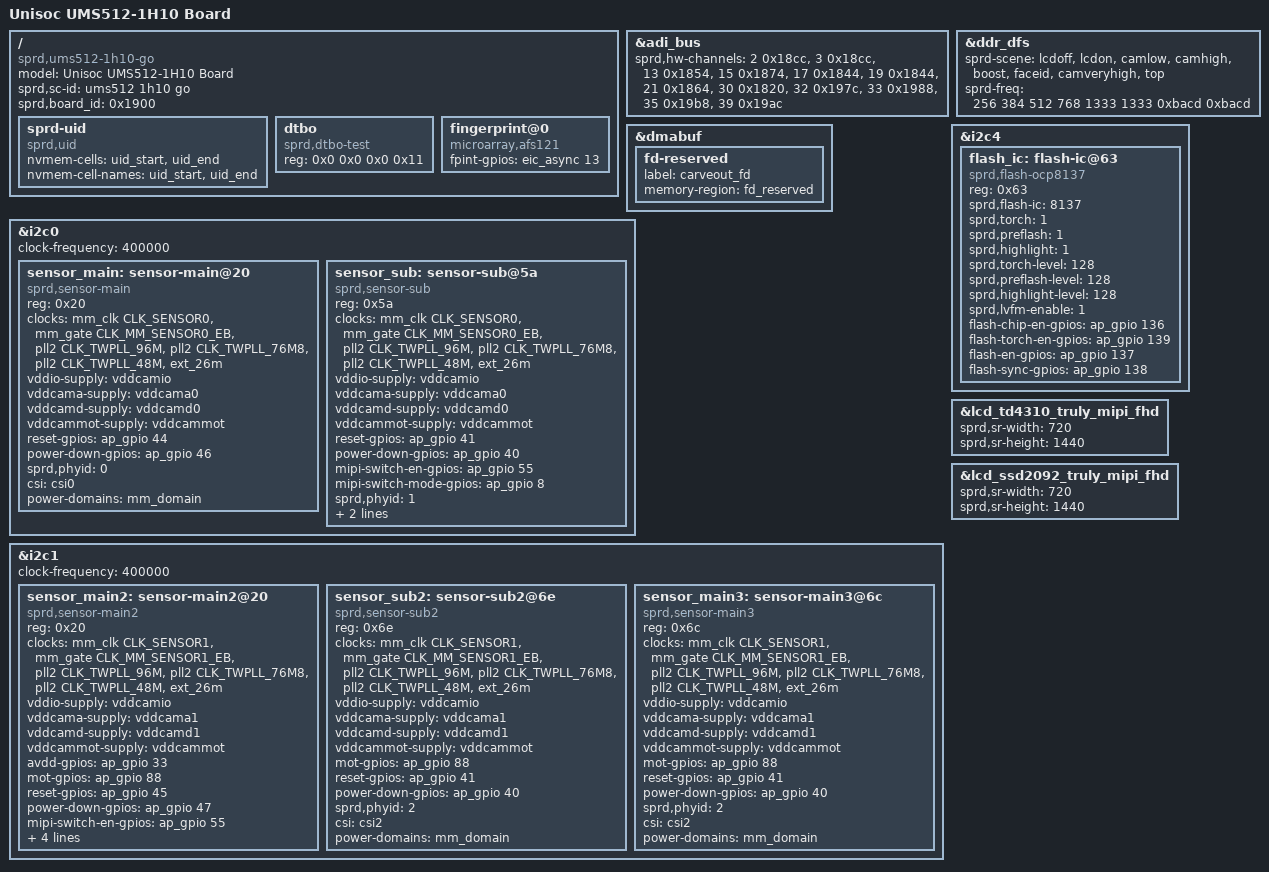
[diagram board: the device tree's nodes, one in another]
/dts-v1/;
/plugin/;

#include <dt-bindings/clock/sprd,ums512-clk.h>
#include <dt-bindings/gpio/gpio.h>
#include <dt-bindings/interrupt-controller/arm-gic.h>
#include "lcd/lcd_td4310_truly_mipi_fhd.dtsi"
#include "lcd/lcd_ssd2092_truly_mipi_fhd.dtsi"
#include "lcd/lcd_dummy_mipi.dtsi"
#include "reserved-memory/ums512-1h10-go-overlay.dtsi"
#include "battery/ums512-1h10-go-overlay.dtsi"
#include "touchscreen/ums512-i2c3-gpio144-145-tp.dtsi"

/ {
	model = "Unisoc UMS512-1H10 Board";
	compatible = "sprd,ums512-1h10-go", "sprd,ums512";
	sprd,sc-id = "ums512 1h10 go";
	sprd,board_id = <0x1900>; //XX00:base board,XX00~XXFF:customize board

	fragment {
		target-path = "/";
		__overlay__ {
			#address-cells = <2>;
			#size-cells = <2>;

			dtbo: dtbo {
				compatible = "sprd,dtbo-test";
				reg = <0x0 0x0 0x0 0x11>;
			};

			fingerprint@0 {
				compatible = "microarray,afs121";
				fpint-gpios = <&eic_async 13 0>;
			};

		};
	};

	sprd-uid {
		compatible = "sprd,uid";
		nvmem-cells = <&uid_start>, <&uid_end>;
		nvmem-cell-names = "uid_start", "uid_end";
	};

};

&adi_bus {
	sprd,hw-channels = <2 0x18cc>, <3 0x18cc>, <13 0x1854>, <15 0x1874>,
			 <17 0x1844>, <19 0x1844>, <21 0x1864>, <30 0x1820>,
			 <32 0x197c>, <33 0x1988>, <35 0x19b8>, <39 0x19ac>;
};

&ddr_dfs {
	sprd-scene = "lcdoff", "lcdon", "camlow", "camhigh",
		"boost", "faceid", "camveryhigh", "top";
	sprd-freq = <256 384 512 768 1333 1333 0xbacd 0xbacd>;
};

&dmabuf {
	fd-reserved {
		label = "carveout_fd";
		memory-region = <&fd_reserved>;
	};
};

&i2c0 {
	#address-cells = <1>;
	#size-cells = <0>;

	status = "okay";
	clock-frequency = <400000>;

	sensor_main: sensor-main@20 {
		compatible = "sprd,sensor-main";
		reg = <0x20>;
		clock-names = "clk_src","sensor_eb",
			"clk_96m","clk_76m8",
			"clk_48m","clk_26m";
		clocks = <&mm_clk CLK_SENSOR0>,<&mm_gate CLK_MM_SENSOR0_EB>,
				<&pll2 CLK_TWPLL_96M>,<&pll2 CLK_TWPLL_76M8>,
				<&pll2 CLK_TWPLL_48M>,<&ext_26m>;
		vddio-supply = <&vddcamio>;
		vddcama-supply = <&vddcama0>;
		vddcamd-supply = <&vddcamd0>;
		vddcammot-supply = <&vddcammot>;
		reset-gpios = <&ap_gpio 44 0>;
		power-down-gpios = <&ap_gpio 46 0>;
		sprd,phyid = <0>;
		csi = <&csi0>;
		power-domains = <&mm_domain>;
	};

	sensor_sub: sensor-sub@5a {
		compatible = "sprd,sensor-sub";
		reg = <0x5a>;
		clock-names = "clk_src","sensor_eb",
			"clk_96m","clk_76m8",
			"clk_48m","clk_26m";
		clocks = <&mm_clk CLK_SENSOR0>,<&mm_gate CLK_MM_SENSOR0_EB>,
				<&pll2 CLK_TWPLL_96M>,<&pll2 CLK_TWPLL_76M8>,
				<&pll2 CLK_TWPLL_48M>,<&ext_26m>;
		vddio-supply = <&vddcamio>;
		vddcama-supply = <&vddcama0>;
		vddcamd-supply = <&vddcamd0>;
		vddcammot-supply = <&vddcammot>;
		reset-gpios = <&ap_gpio 41 0>;
		power-down-gpios = <&ap_gpio 40 0>;
		mipi-switch-en-gpios = <&ap_gpio 55 0>;
		mipi-switch-mode-gpios = <&ap_gpio 8 0>;
		sprd,phyid = <1>;
		csi = <&csi1>;
		power-domains = <&mm_domain>;
	};
};

&i2c1 {
	#address-cells = <1>;
	#size-cells = <0>;

	status = "okay";
	clock-frequency = <400000>;

	sensor_main2: sensor-main2@20 {
		compatible = "sprd,sensor-main2";
		reg = <0x20>;
		clock-names = "clk_src","sensor_eb",
			"clk_96m","clk_76m8",
			"clk_48m","clk_26m";
		clocks = <&mm_clk CLK_SENSOR1>,<&mm_gate CLK_MM_SENSOR1_EB>,
				<&pll2 CLK_TWPLL_96M>,<&pll2 CLK_TWPLL_76M8>,
				<&pll2 CLK_TWPLL_48M>,<&ext_26m>;
		vddio-supply = <&vddcamio>;
		vddcama-supply = <&vddcama1>;
		vddcamd-supply = <&vddcamd1>;
		vddcammot-supply = <&vddcammot>;
		avdd-gpios = <&ap_gpio 33 0>;
		mot-gpios = <&ap_gpio 88 0>;
		reset-gpios = <&ap_gpio 45 0>;
		power-down-gpios = <&ap_gpio 47 0>;
		mipi-switch-en-gpios = <&ap_gpio 55 0>;
		mipi-switch-mode-gpios = <&ap_gpio 8 0>;
		sprd,phyid = <1>;
		csi = <&csi1>;
		power-domains = <&mm_domain>;
	};

	sensor_sub2: sensor-sub2@6e {
		compatible = "sprd,sensor-sub2";
		reg = <0x6e>;
		clock-names = "clk_src","sensor_eb",
			"clk_96m","clk_76m8",
			"clk_48m","clk_26m";
		clocks = <&mm_clk CLK_SENSOR1>,<&mm_gate CLK_MM_SENSOR1_EB>,
			<&pll2 CLK_TWPLL_96M>,<&pll2 CLK_TWPLL_76M8>,
			<&pll2 CLK_TWPLL_48M>,<&ext_26m>;
		vddio-supply = <&vddcamio>;
		vddcama-supply = <&vddcama1>;
		vddcamd-supply = <&vddcamd1>;
		vddcammot-supply = <&vddcammot>;
		mot-gpios = <&ap_gpio 88 0>;
		reset-gpios = <&ap_gpio 41 0>;
		power-down-gpios = <&ap_gpio 40 0>;
		sprd,phyid = <2>;
		csi = <&csi2>;
		power-domains = <&mm_domain>;
	};

	sensor_main3: sensor-main3@6c {
		compatible = "sprd,sensor-main3";
		reg = <0x6c>;
		clock-names = "clk_src","sensor_eb",
			"clk_96m","clk_76m8",
			"clk_48m","clk_26m";
		clocks = <&mm_clk CLK_SENSOR1>,<&mm_gate CLK_MM_SENSOR1_EB>,
				<&pll2 CLK_TWPLL_96M>,<&pll2 CLK_TWPLL_76M8>,
				<&pll2 CLK_TWPLL_48M>,<&ext_26m>;
		vddio-supply = <&vddcamio>;
		vddcama-supply = <&vddcama1>;
		vddcamd-supply = <&vddcamd1>;
		vddcammot-supply = <&vddcammot>;
		mot-gpios = <&ap_gpio 88 0>;
		reset-gpios = <&ap_gpio 41 0>;
		power-down-gpios = <&ap_gpio 40 0>;
		sprd,phyid = <2>;
		csi = <&csi2>;
		power-domains = <&mm_domain>;
	};
};

&i2c4 {
	status = "okay";

	flash_ic: flash-ic@63 {
		compatible = "sprd,flash-ocp8137";
		reg = <0x63>;
		sprd,flash-ic = <8137>;
		sprd,torch = <1>;
		sprd,preflash = <1>;
		sprd,highlight = <1>;
		sprd,torch-level = <128>;
		sprd,preflash-level = <128>;
		sprd,highlight-level = <128>;
		sprd,lvfm-enable = <1>;
		flash-chip-en-gpios = <&ap_gpio 136 0>;
		flash-torch-en-gpios = <&ap_gpio 139 0>;
		flash-en-gpios = <&ap_gpio 137 0>;
		flash-sync-gpios = <&ap_gpio 138 0>;
	};
};

&lcd_td4310_truly_mipi_fhd {
	sprd,sr-width = <720>;
	sprd,sr-height = <1440>;
};

&lcd_ssd2092_truly_mipi_fhd {
	sprd,sr-width = <720>;
	sprd,sr-height = <1440>;
};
